# STM32H743 register map
File version: 2.4
CPU: CM7 r0p1, little endian, MPU, FPU, 4 interrupt priority bits
Registers are 32-bit, read-write, reset 0x0 unless marked. A register's access mark holds for its fields unless they carry their own. Offsets are from the block's base; [hi:lo] are bit positions; {n}, {i} and the like mark numbered series.

## FDCAN1
Base 0x4000A000
Same registers: FDCAN2 0x4000A400
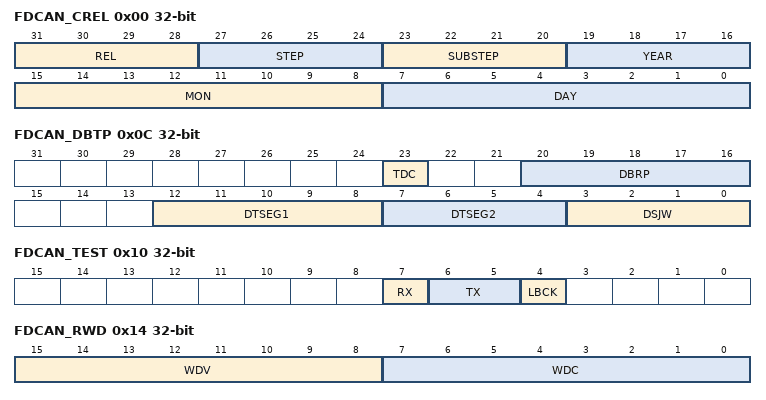
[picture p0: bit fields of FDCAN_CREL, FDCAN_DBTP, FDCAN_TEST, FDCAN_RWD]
0x00 FDCAN_CREL ro — FDCAN 内核版本寄存器
  [31:28] REL — 内核版本号
  [27:24] STEP — 内核版本步进号
  [23:20] SUBSTEP — 内核版本子步进号
  [19:16] YEAR — 时间戳 年份
  [15:8] MON — 时间戳 月份
  [7:0] DAY — 时间戳 日期
0x04 FDCAN_ENDN ro — FDCAN 字节序寄存器
  [31:0] ETV — 字节序测试值
0x0C FDCAN_DBTP ro — FDCAN 数据位时序与预分频器寄存器
  [23] TDC — 收发器延迟补偿
  [20:16] DBRP — 数据位速率预分频器
  [12:8] DTSEG1 — 数据位采样点前时间段
  [7:4] DTSEG2 — 数据位采样点后时间段
  [3:0] DSJW — 同步跳变宽度
0x10 FDCAN_TEST ro — FDCAN 测试寄存器
  [7] RX — 接收引脚状态
  [6:5] TX — 发送引脚控制
  [4] LBCK — 环回模式
0x14 FDCAN_RWD ro — FDCAN RAM 看门狗寄存器
  [15:8] WDV — 看门狗计数值
  [7:0] WDC — 看门狗配置
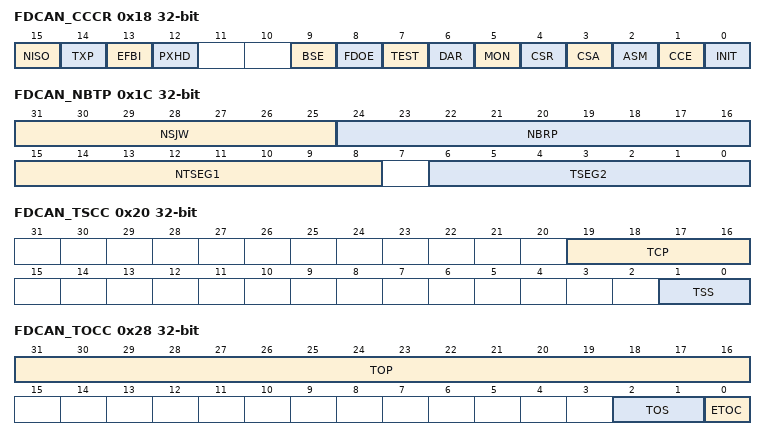
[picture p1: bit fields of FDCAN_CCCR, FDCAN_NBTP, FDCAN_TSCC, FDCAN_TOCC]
0x18 FDCAN_CCCR — FDCAN CC 控制寄存器
  [15] NISO — 非 ISO 模式
  [14] TXP
  [13] EFBI — 总线集成边沿滤波
  [12] PXHD — 禁止协议异常处理
  [9] BSE — FDCAN 位速率切换
  [8] FDOE — FD 工作模式使能
  [7] TEST — 测试模式使能
  [6] DAR — 禁止自动重传
  [5] MON — 总线监听模式
  [4] CSR — 时钟停止请求
  [3] CSA — 时钟停止确认
  [2] ASM — ASM 受限工作模式
  [1] CCE — 配置变更使能
  [0] INIT — 初始化
0x1C FDCAN_NBTP — FDCAN 标称位时序与预分频器寄存器
  [31:25] NSJW — 标称（重）同步跳变宽度
  [24:16] NBRP — 位速率预分频器
  [15:8] NTSEG1 — 标称采样点前时间段
  [6:0] TSEG2 — 标称采样点后时间段
0x20 FDCAN_TSCC — FDCAN 时间戳计数器配置寄存器
  [19:16] TCP — 时间戳计数器预分频器
  [1:0] TSS — 时间戳选择
0x24 FDCAN_TSCV — FDCAN 时间戳计数器数值寄存器
  [15:0] TSC — 时间戳计数器
0x28 FDCAN_TOCC — FDCAN 超时计数器配置寄存器
  [31:16] TOP — 超时周期
  [2:1] TOS — 超时选择
  [0] ETOC — 使能超时计数器
0x2C FDCAN_TOCV — FDCAN 超时计数器数值寄存器
  [15:0] TOC — 超时计数器
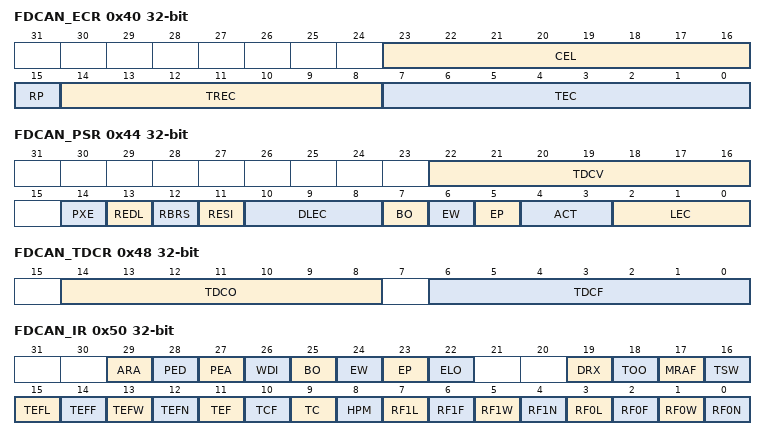
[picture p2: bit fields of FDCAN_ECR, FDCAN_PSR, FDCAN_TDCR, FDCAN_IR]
0x40 FDCAN_ECR — FDCAN 错误计数器寄存器
  [23:16] CEL — CAN 错误记录
  [15] RP — 接收错误被动
  [14:8] TREC — 接收错误计数器
  [7:0] TEC — 发送错误计数器
0x44 FDCAN_PSR — FDCAN 协议状态寄存器
  [22:16] TDCV — 发送器延迟补偿值
  [14] PXE — 协议异常事件
  [13] REDL — 接收到 FDCAN 报文
  [12] RBRS — 上一次接收 FDCAN 报文的 BRS 标志
  [11] RESI — 上一次接收 FDCAN 报文的 ESI 标志
  [10:8] DLEC — 数据阶段上一次错误码
  [7] BO — 总线关闭状态
  [6] EW — 警告状态
  [5] EP — 错误被动
  [4:3] ACT — 活动状态
  [2:0] LEC — 上一次错误码
0x48 FDCAN_TDCR ro — FDCAN 发送器延迟补偿寄存器
  [14:8] TDCO — 发送器延迟补偿偏移
  [6:0] TDCF — 发送器延迟补偿滤波窗口长度
0x50 FDCAN_IR ro — FDCAN 中断寄存器
  [29] ARA — 访问保留地址
  [28] PED — 数据阶段协议错误（使用数据位时间）
  [27] PEA — 仲裁阶段协议错误（使用标称位时间）
  [26] WDI — 看门狗中断
  [25] BO — 总线关闭状态
  [24] EW — 警告状态
  [23] EP — 错误被动
  [22] ELO — 错误记录溢出
  [19] DRX — 报文存入专用 Rx 缓冲区
  [18] TOO — 超时发生
  [17] MRAF — 消息 RAM 访问失败
  [16] TSW — 时间戳回绕
  [15] TEFL — Tx 事件 FIFO 条目丢失
  [14] TEFF — Tx 事件 FIFO 满
  [13] TEFW — Tx 事件 FIFO 达到水位线
  [12] TEFN — Tx 事件 FIFO 新条目
  [11] TEF — Tx FIFO 空
  [10] TCF — 发送取消完成
  [9] TC — 发送完成
  [8] HPM — 高优先级报文
  [7] RF1L — Rx FIFO 1 报文丢失
  [6] RF1F — Rx FIFO 1 满
  [5] RF1W — Rx FIFO 1 达到水位线
  [4] RF1N — Rx FIFO 1 新报文
  [3] RF0L — Rx FIFO 0 报文丢失
  [2] RF0F — Rx FIFO 0 满
  [1] RF0W — Rx FIFO 0 达到水位线
  [0] RF0N — Rx FIFO 0 新报文
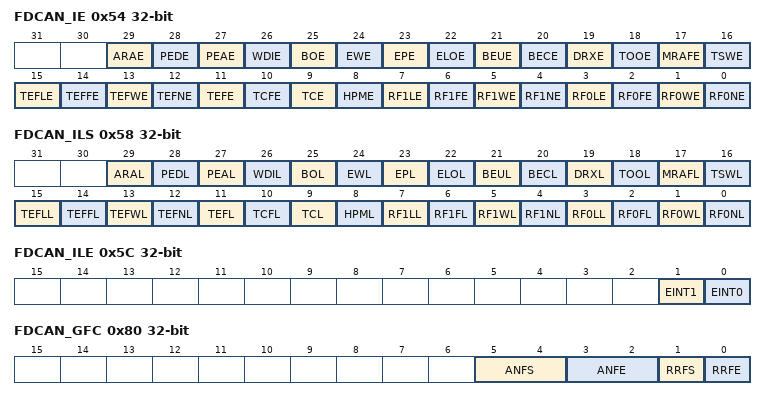
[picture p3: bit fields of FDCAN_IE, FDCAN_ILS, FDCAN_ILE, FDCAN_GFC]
0x54 FDCAN_IE ro — FDCAN 中断使能寄存器
  [29] ARAE — 访问保留地址中断使能
  [28] PEDE — 数据阶段协议错误中断使能
  [27] PEAE — 仲裁阶段协议错误中断使能
  [26] WDIE — 看门狗中断使能
  [25] BOE — 总线关闭状态中断使能
  [24] EWE — 警告状态中断使能
  [23] EPE — 错误被动中断使能
  [22] ELOE — 错误记录溢出中断使能
  [21] BEUE — 位错误未纠正中断使能
  [20] BECE — 位错误已纠正中断使能
  [19] DRXE — 报文存入专用 Rx 缓冲区中断使能
  [18] TOOE — 超时发生中断使能
  [17] MRAFE — 消息 RAM 访问失败中断使能
  [16] TSWE — 时间戳回绕中断使能
  [15] TEFLE — Tx 事件 FIFO 条目丢失中断使能
  [14] TEFFE — Tx 事件 FIFO 满中断使能
  [13] TEFWE — Tx 事件 FIFO 达到水位线中断使能
  [12] TEFNE — Tx 事件 FIFO 新条目中断使能
  [11] TEFE — Tx FIFO 空中断使能
  [10] TCFE — 发送取消完成中断使能
  [9] TCE — 发送完成中断使能
  [8] HPME — 高优先级报文中断使能
  [7] RF1LE — Rx FIFO 1 报文丢失中断使能
  [6] RF1FE — Rx FIFO 1 满中断使能
  [5] RF1WE — Rx FIFO 1 达到水位线中断使能
  [4] RF1NE — Rx FIFO 1 新报文中断使能
  [3] RF0LE — Rx FIFO 0 报文丢失中断使能
  [2] RF0FE — Rx FIFO 0 满中断使能
  [1] RF0WE — Rx FIFO 0 达到水位线中断使能
  [0] RF0NE — Rx FIFO 0 新报文中断使能
0x58 FDCAN_ILS ro — FDCAN 中断线选择寄存器
  [29] ARAL — 访问保留地址中断线
  [28] PEDL — 数据阶段协议错误中断线
  [27] PEAL — 仲裁阶段协议错误中断线
  [26] WDIL — 看门狗中断线
  [25] BOL — 总线关闭状态
  [24] EWL — 警告状态中断线
  [23] EPL — 错误被动中断线
  [22] ELOL — 错误记录溢出中断线
  [21] BEUL — 位错误未纠正中断线
  [20] BECL — 位错误已纠正中断线
  [19] DRXL — 报文存入专用 Rx 缓冲区中断线
  [18] TOOL — 超时发生中断线
  [17] MRAFL — 消息 RAM 访问失败中断线
  [16] TSWL — 时间戳回绕中断线
  [15] TEFLL — Tx 事件 FIFO 条目丢失中断线
  [14] TEFFL — Tx 事件 FIFO 满中断线
  [13] TEFWL — Tx 事件 FIFO 达到水位线中断线
  [12] TEFNL — Tx 事件 FIFO 新条目中断线
  [11] TEFL — Tx FIFO 空中断线
  [10] TCFL — 发送取消完成中断线
  [9] TCL — 发送完成中断线
  [8] HPML — 高优先级报文中断线
  [7] RF1LL — Rx FIFO 1 报文丢失中断线
  [6] RF1FL — Rx FIFO 1 满中断线
  [5] RF1WL — Rx FIFO 1 达到水位线中断线
  [4] RF1NL — Rx FIFO 1 新报文中断线
  [3] RF0LL — Rx FIFO 0 报文丢失中断线
  [2] RF0FL — Rx FIFO 0 满中断线
  [1] RF0WL — Rx FIFO 0 达到水位线中断线
  [0] RF0NL — Rx FIFO 0 新报文中断线
0x5C FDCAN_ILE — FDCAN 中断线使能寄存器
  [1] EINT1 — 使能中断线 1
  [0] EINT0 — 使能中断线 0
0x80 FDCAN_GFC — FDCAN 全局滤波器配置寄存器
  [5:4] ANFS — 接收不匹配的标准帧
  [3:2] ANFE — 接收不匹配的扩展帧
  [1] RRFS — 拒绝标准远程帧
  [0] RRFE — 拒绝扩展远程帧
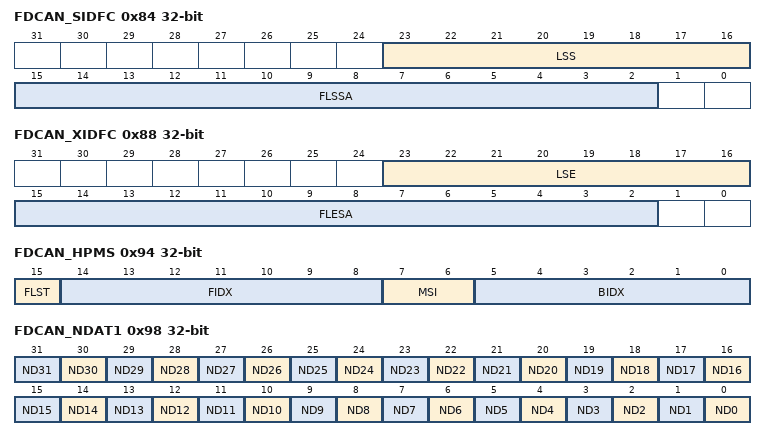
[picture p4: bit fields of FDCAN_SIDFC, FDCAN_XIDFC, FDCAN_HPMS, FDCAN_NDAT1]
0x84 FDCAN_SIDFC — FDCAN 标准 ID 滤波器配置寄存器
  [23:16] LSS — 标准列表大小
  [15:2] FLSSA — 标准滤波器列表起始地址
0x88 FDCAN_XIDFC — FDCAN 扩展 ID 滤波器配置寄存器
  [23:16] LSE — 扩展列表大小
  [15:2] FLESA — 扩展滤波器列表起始地址
0x90 FDCAN_XIDAM — FDCAN 扩展 ID 与掩码寄存器
  [28:0] EIDM — 扩展 ID 掩码
0x94 FDCAN_HPMS ro — FDCAN 高优先级报文状态寄存器
  [15] FLST — 滤波器列表
  [14:8] FIDX — 滤波器索引
  [7:6] MSI — 报文存储指示
  [5:0] BIDX — 缓冲区索引
0x98 FDCAN_NDAT1 ro — FDCAN 新数据 1 寄存器
  [n] ND{n} (n=0..31) — 新数据到达
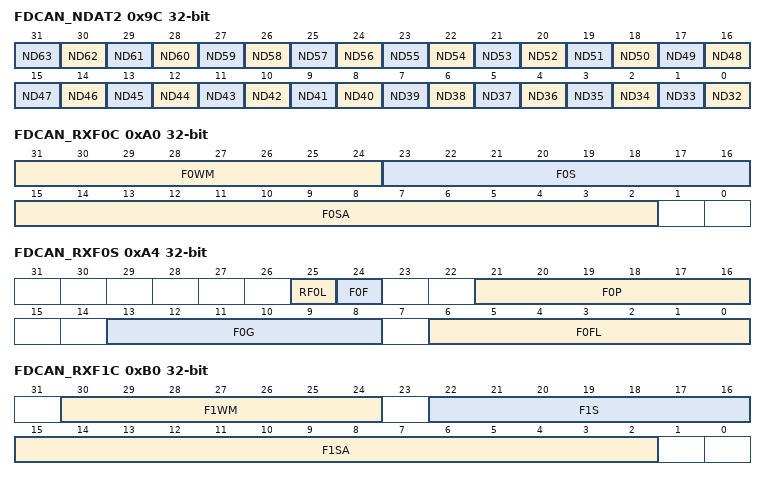
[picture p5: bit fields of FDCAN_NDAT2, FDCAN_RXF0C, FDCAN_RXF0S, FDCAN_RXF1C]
0x9C FDCAN_NDAT2 ro — FDCAN 新数据 2 寄存器
  [n-32] ND{n} (n=32..63) — 新数据到达
0xA0 FDCAN_RXF0C — FDCAN Rx FIFO 0 配置寄存器
  [31:24] F0WM — FIFO 0 水位线
  [23:16] F0S — Rx FIFO 0 大小
  [15:2] F0SA — Rx FIFO 0 起始地址
0xA4 FDCAN_RXF0S — FDCAN Rx FIFO 0 状态寄存器
  [25] RF0L — Rx FIFO 0 报文丢失
  [24] F0F — Rx FIFO 0 满
  [21:16] F0P — Rx FIFO 0 写入索引
  [13:8] F0G — Rx FIFO 0 读取索引
  [6:0] F0FL — Rx FIFO 0 填充级别
0xA8 FDCAN_RXF0A — FDCAN Rx FIFO 0 确认寄存器
  [5:0] FA01 — Rx FIFO 0 确认索引
0xAC FDCAN_RXBC — FDCAN Rx 缓冲区配置寄存器
  [15:2] RBSA — Rx 缓冲区起始地址
0xB0 FDCAN_RXF1C — FDCAN Rx FIFO 1 配置寄存器
  [30:24] F1WM — Rx FIFO 1 水位线
  [22:16] F1S — Rx FIFO 1 大小
  [15:2] F1SA — Rx FIFO 1 起始地址
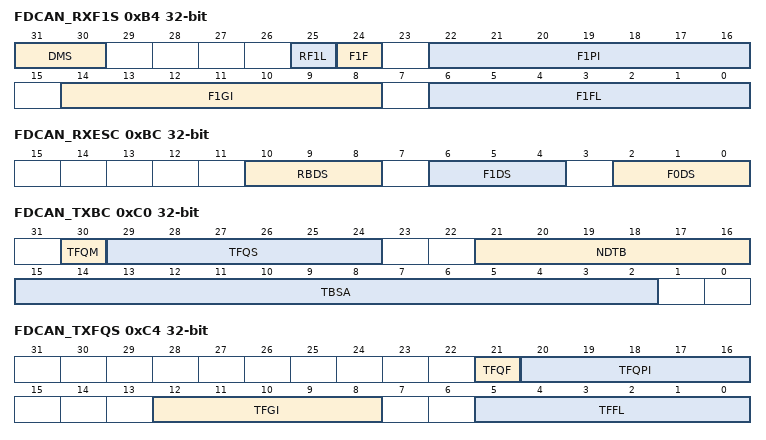
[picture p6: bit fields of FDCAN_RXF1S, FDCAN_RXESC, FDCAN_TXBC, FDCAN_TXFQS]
0xB4 FDCAN_RXF1S — FDCAN Rx FIFO 1 状态寄存器
  [31:30] DMS — 调试报文状态
  [25] RF1L — Rx FIFO 1 报文丢失
  [24] F1F — Rx FIFO 1 满
  [22:16] F1PI — Rx FIFO 1 写入索引
  [14:8] F1GI — Rx FIFO 1 读取索引
  [6:0] F1FL — Rx FIFO 1 填充级别
0xB8 FDCAN_RXF1A — FDCAN Rx FIFO 1 确认寄存器
  [5:0] F1AI — Rx FIFO 1 确认索引
0xBC FDCAN_RXESC — FDCAN Rx 缓冲区元素大小配置寄存器
  [10:8] RBDS — Rx 缓冲区数据字段大小
  [6:4] F1DS — Rx FIFO 1 数据字段大小
  [2:0] F0DS — Rx FIFO 0 数据字段大小
0xC0 FDCAN_TXBC — FDCAN Tx 缓冲区配置寄存器
  [30] TFQM — Tx FIFO/队列模式
  [29:24] TFQS — 发送 FIFO/队列大小
  [21:16] NDTB — 专用发送缓冲区数量
  [15:2] TBSA — Tx 缓冲区起始地址
0xC4 FDCAN_TXFQS ro — FDCAN Tx FIFO/队列状态寄存器
  [21] TFQF — Tx FIFO/队列满
  [20:16] TFQPI — Tx FIFO/队列写入索引
  [12:8] TFGI — Tx FIFO 读取索引
  [5:0] TFFL — Tx FIFO 空闲级别
0xC8 FDCAN_TXESC — FDCAN Tx 缓冲区元素大小配置寄存器
  [2:0] TBDS — Tx 缓冲区数据字段大小
0xCC FDCAN_TXBRP ro — FDCAN Tx 缓冲区请求挂起寄存器
  [31:0] TRP — 发送请求挂起
0xD0 FDCAN_TXBAR — FDCAN Tx 缓冲区添加请求寄存器
  [31:0] AR — 添加请求
0xD4 FDCAN_TXBCR — FDCAN Tx 缓冲区取消请求寄存器
  [31:0] CR — 取消请求
0xD8 FDCAN_TXBTO — FDCAN Tx 缓冲区已发送寄存器
  [31:0] TO — 发送已完成
0xDC FDCAN_TXBCF ro — FDCAN Tx 缓冲区取消完成寄存器
  [31:0] CF — 取消完成
0xE0 FDCAN_TXBTIE — FDCAN Tx 缓冲区发送中断使能寄存器
  [31:0] TIE — 发送中断使能
0xE4 FDCAN_TXBCIE — FDCAN Tx 缓冲区取消完成中断使能寄存器
  [31:0] CF — 取消完成中断使能
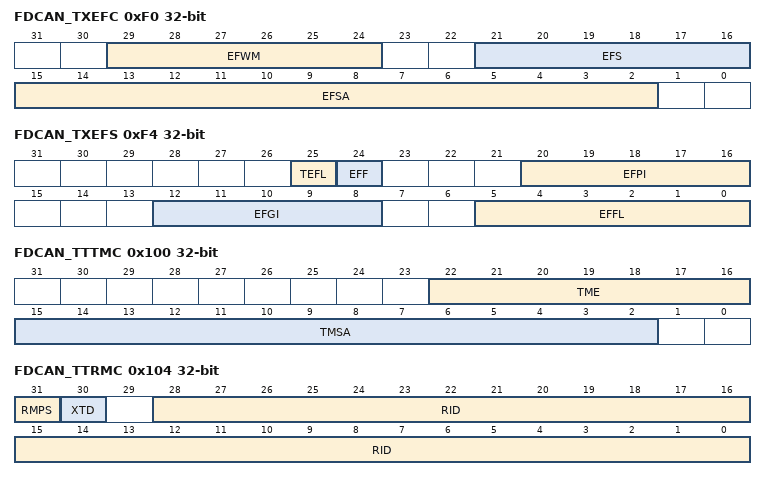
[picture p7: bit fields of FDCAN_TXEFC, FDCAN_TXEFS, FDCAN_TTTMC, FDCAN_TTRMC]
0xF0 FDCAN_TXEFC — FDCAN Tx 事件 FIFO 配置寄存器
  [29:24] EFWM — 事件 FIFO 水位线
  [21:16] EFS — 事件 FIFO 大小
  [15:2] EFSA — 事件 FIFO 起始地址
0xF4 FDCAN_TXEFS — FDCAN Tx 事件 FIFO 状态寄存器
  [25] TEFL — Tx 事件 FIFO 条目丢失
  [24] EFF — 事件 FIFO 满
  [20:16] EFPI — 事件 FIFO 写入索引
  [12:8] EFGI — 事件 FIFO 读取索引
  [5:0] EFFL — 事件 FIFO 填充级别
0xF8 FDCAN_TXEFA — FDCAN Tx 事件 FIFO 确认寄存器
  [4:0] EFAI — 事件 FIFO 确认索引
0x100 FDCAN_TTTMC — FDCAN TT 触发存储器配置寄存器
  [22:16] TME — 触发存储器元素数量
  [15:2] TMSA — 触发存储器起始地址
0x104 FDCAN_TTRMC — FDCAN TT 参考报文配置寄存器
  [31] RMPS — 参考报文负载选择
  [30] XTD — 扩展标识符
  [28:0] RID — 参考标识符
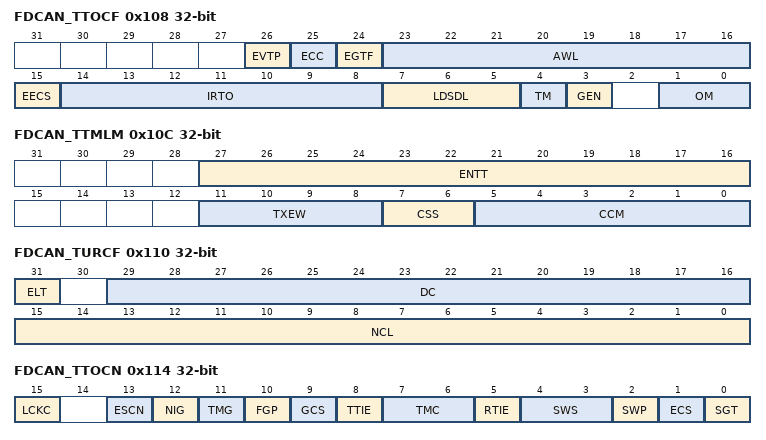
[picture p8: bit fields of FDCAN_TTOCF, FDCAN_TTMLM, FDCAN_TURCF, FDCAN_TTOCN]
0x108 FDCAN_TTOCF — FDCAN TT 工作配置寄存器
  [26] EVTP — 事件触发极性
  [25] ECC — 使能时钟校准
  [24] EGTF — 使能全局时间滤波
  [23:16] AWL — 应用看门狗限制
  [15] EECS — 使能外部时钟同步
  [14:8] IRTO — 初始参考触发偏移
  [7:5] LDSDL — 同步偏差限制值
  [4] TM — 时间主控
  [3] GEN — 间隔使能
  [1:0] OM — 工作模式
0x10C FDCAN_TTMLM — FDCAN TT 矩阵限制寄存器
  [27:16] ENTT — 预期 Tx 触发数量
  [11:8] TXEW — Tx 使能窗口
  [7:6] CSS — 循环起始同步
  [5:0] CCM — 最大循环计数
0x110 FDCAN_TURCF — FDCAN TUR 配置寄存器
  [31] ELT — 使能本地时间
  [29:16] DC — 分母配置
  [15:0] NCL — 分子配置低字
0x114 FDCAN_TTOCN — FDCAN TT 工作控制寄存器
  [15] LCKC — TT 工作控制寄存器已锁定
  [13] ESCN — 外部同步控制
  [12] NIG — 下一周期为间隔
  [11] TMG — 时间标记间隔
  [10] FGP — 结束间隔
  [9] GCS — 间隔控制选择
  [8] TTIE — 触发时间标记中断脉冲使能
  [7:6] TMC — 寄存器时间标记比较
  [5] RTIE — 寄存器时间标记中断脉冲使能
  [4:3] SWS — 秒表源
  [2] SWP — 秒表极性
  [1] ECS — 外部时钟同步
  [0] SGT — 设置全局时间
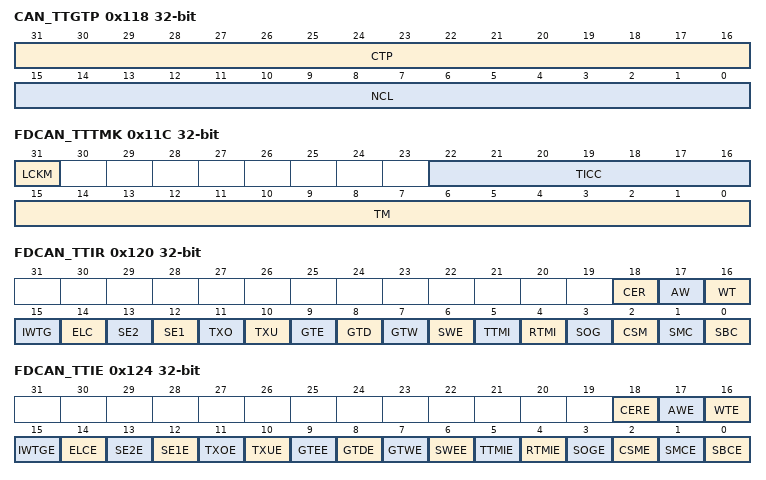
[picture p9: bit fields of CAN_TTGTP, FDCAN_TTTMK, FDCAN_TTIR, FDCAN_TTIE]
0x118 CAN_TTGTP — FDCAN TT 全局时间预设寄存器
  [31:16] CTP — 循环时间目标相位
  [15:0] NCL — 时间预设
0x11C FDCAN_TTTMK — FDCAN TT 时间标记寄存器
  [31] LCKM — TT 时间标记寄存器已锁定
  [22:16] TICC — 时间标记循环码
  [15:0] TM — 时间标记
0x120 FDCAN_TTIR — FDCAN TT 中断寄存器
  [18] CER — 配置错误
  [17] AW — 应用看门狗
  [16] WT — 监视触发
  [15] IWTG — 初始化监视触发
  [14] ELC — 错误级别变更
  [13] SE2 — 调度错误 2
  [12] SE1 — 调度错误 1
  [11] TXO — Tx 计数上溢
  [10] TXU — Tx 计数下溢
  [9] GTE — 全局时间错误
  [8] GTD — 全局时间不连续
  [7] GTW — 全局时间回绕
  [6] SWE — 秒表事件
  [5] TTMI — 触发时间标记内部事件
  [4] RTMI — 寄存器时间标记中断
  [3] SOG — 间隔开始
  [2] CSM — 同步模式变更
  [1] SMC — 矩阵循环开始
  [0] SBC — 基本循环开始
0x124 FDCAN_TTIE — FDCAN TT 中断使能寄存器
  [18] CERE — 配置错误中断使能
  [17] AWE — 应用看门狗中断使能
  [16] WTE — 监视触发中断使能
  [15] IWTGE — 初始化监视触发中断使能
  [14] ELCE — 错误级别变更中断使能
  [13] SE2E — 调度错误 2 中断使能
  [12] SE1E — 调度错误 1 中断使能
  [11] TXOE — Tx 计数上溢中断使能
  [10] TXUE — Tx 计数下溢中断使能
  [9] GTEE — 全局时间错误中断使能
  [8] GTDE — 全局时间不连续中断使能
  [7] GTWE — 全局时间回绕中断使能
  [6] SWEE — 秒表事件中断使能
  [5] TTMIE — 触发时间标记内部事件中断使能
  [4] RTMIE — 寄存器时间标记中断使能
  [3] SOGE — 间隔开始中断使能
  [2] CSME — 同步模式变更中断使能
  [1] SMCE — 矩阵循环开始中断使能
  [0] SBCE — 基本循环开始中断使能
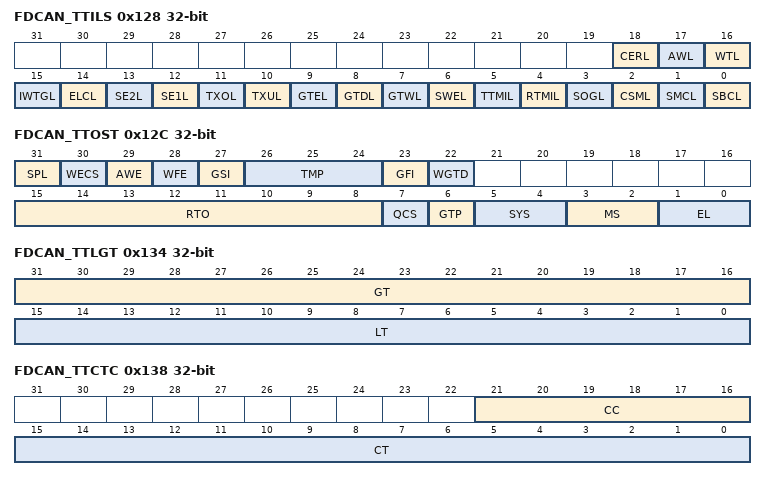
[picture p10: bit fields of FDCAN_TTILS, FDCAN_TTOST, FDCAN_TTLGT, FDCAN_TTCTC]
0x128 FDCAN_TTILS — FDCAN TT 中断线选择寄存器
  [18] CERL — 配置错误中断线
  [17] AWL — 应用看门狗中断线
  [16] WTL — 监视触发中断线
  [15] IWTGL — 初始化监视触发中断线
  [14] ELCL — 错误级别变更中断线
  [13] SE2L — 调度错误 2 中断线
  [12] SE1L — 调度错误 1 中断线
  [11] TXOL — Tx 计数上溢中断线
  [10] TXUL — Tx 计数下溢中断线
  [9] GTEL — 全局时间错误中断线
  [8] GTDL — 全局时间不连续中断线
  [7] GTWL — 全局时间回绕中断线
  [6] SWEL — 秒表事件中断线
  [5] TTMIL — 触发时间标记内部事件中断线
  [4] RTMIL — 寄存器时间标记中断线
  [3] SOGL — 间隔开始中断线
  [2] CSML — 同步模式变更中断线
  [1] SMCL — 矩阵循环开始中断线
  [0] SBCL — 基本循环开始中断线
0x12C FDCAN_TTOST — FDCAN TT 工作状态寄存器
  [31] SPL — 调度相位锁定
  [30] WECS — 等待外部时钟同步
  [29] AWE — 应用看门狗事件
  [28] WFE — 等待事件
  [27] GSI — 间隔开始指示
  [26:24] TMP — 时间主控优先级
  [23] GFI — 间隔结束指示
  [22] WGTD — 等待全局时间不连续
  [15:8] RTO — 参考触发偏移
  [7] QCS — 时钟速度质量
  [6] GTP — 全局时间相位质量
  [5:4] SYS — 同步状态
  [3:2] MS — 主控状态
  [1:0] EL — 错误级别
0x130 FDCAN_TURNA ro — FDCAN TUR 分子实际值寄存器
  [17:0] NAV — 分子实际值
0x134 FDCAN_TTLGT ro — FDCAN TT 本地与全局时间寄存器
  [31:16] GT — 全局时间
  [15:0] LT — 本地时间
0x138 FDCAN_TTCTC ro — FDCAN TT 循环时间与计数寄存器
  [21:16] CC — 循环计数
  [15:0] CT — 循环时间
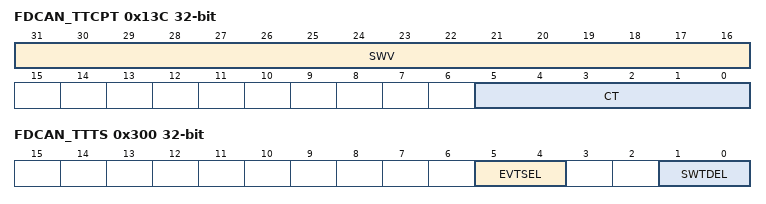
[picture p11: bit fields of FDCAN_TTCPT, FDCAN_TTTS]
0x13C FDCAN_TTCPT ro — FDCAN TT 捕获时间寄存器
  [31:16] SWV — 秒表值
  [5:0] CT — 循环计数值
0x140 FDCAN_TTCSM ro — FDCAN TT 循环同步标记寄存器
  [15:0] CSM — 循环同步标记
0x300 FDCAN_TTTS — FDCAN TT 触发选择寄存器
  [5:4] EVTSEL — 事件触发输入选择
  [1:0] SWTDEL — 秒表触发输入选择
